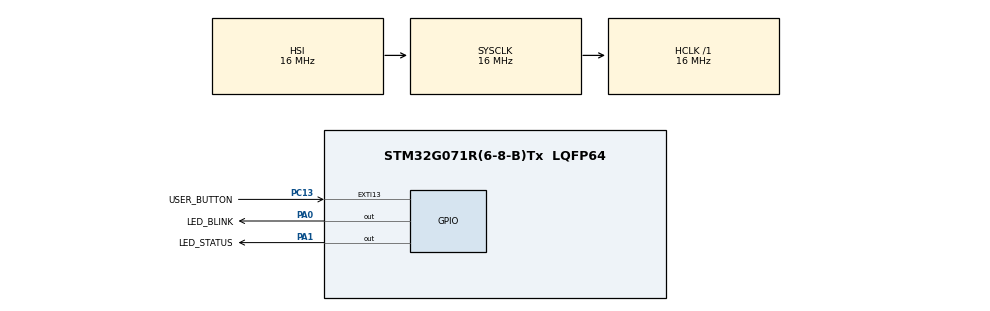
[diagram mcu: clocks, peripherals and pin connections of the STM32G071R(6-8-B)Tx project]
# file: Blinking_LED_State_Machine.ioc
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Mcu.Family=STM32G0
Mcu.Name=STM32G071R(6-8-B)Tx
Mcu.Package=LQFP64
NVIC.EXTI4_15_IRQn=true\:0\:0\:false\:false\:true\:true\:true\:true
NVIC.TIM6_DAC_LPTIM1_IRQn=true\:0\:0\:false\:false\:true\:true\:true\:true
PA0.GPIO_Label=LED_BLINK
PA0.Signal=GPIO_Output
PA1.GPIO_Label=LED_STATUS
PA1.GPIO_Speed=GPIO_SPEED_FREQ_MEDIUM
PA1.PinState=GPIO_PIN_RESET
PA1.Signal=GPIO_Output
PA13.GPIO_Label=TMS
PA13.Signal=SYS_SWDIO
PA14-BOOT0.GPIO_Label=TCK
PA14-BOOT0.Signal=SYS_SWCLK
PC13.GPIO_Label=USER_BUTTON
PC13.GPIO_ModeDefaultEXTI=GPIO_MODE_IT_RISING_FALLING
PC13.GPIO_PuPd=GPIO_PULLUP
PC13.Signal=GPXTI13
PC14-OSC32_IN\ (PC14).Signal=RCC_OSC32_IN
PC15-OSC32_OUT\ (PC15).Signal=RCC_OSC32_OUT
PF0-OSC_IN\ (PF0).GPIO_Label=MCO
PF0-OSC_IN\ (PF0).Signal=RCC_OSC_IN
ProjectManager.HeapSize=0x200
ProjectManager.StackSize=0x400
ProjectManager.TargetToolchain=STM32CubeIDE
RCC.AHBFreq_Value=16000000
RCC.CortexFreq_Value=16000000
RCC.EXTERNAL_CLOCK_VALUE=12288000
RCC.HCLKFreq_Value=16000000
RCC.HSE_VALUE=8000000
RCC.HSI_VALUE=16000000
RCC.LSE_VALUE=32768
RCC.SYSCLKFreq_VALUE=16000000
RCC.VCOOutputFreq_Value=128000000
TIM6.AutoReloadPreload=TIM_AUTORELOAD_PRELOAD_DISABLE
TIM6.Prescaler=16000-1
TIM6.TIM_MasterOutputTrigger=TIM_TRGO_UPDATE
VP_TIM6_VS_ClockSourceINT.Mode=Enable_Timer
board=NUCLEO-G071RB

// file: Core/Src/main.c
/* USER CODE BEGIN Header */
/**
  ******************************************************************************
  * @file           : main.c
  * @brief          : Main program body
  ******************************************************************************
  * @attention
  *
  * Copyright (c) 2023 STMicroelectronics.
  * All rights reserved.
  *
  * This software is licensed under terms that can be found in the LICENSE file
  * in the root directory of this software component.
  * If no LICENSE file comes with this software, it is provided AS-IS.
  *
  ******************************************************************************
  */
/* USER CODE END Header */
#include "main.h"

TIM_HandleTypeDef htim6;

void SystemClock_Config(void);
static void MX_GPIO_Init(void);
static void MX_TIM6_Init(void);

int main(void)
{

  /* MCU Configuration--------------------------------------------------------*/

  /* Reset of all peripherals, Initializes the Flash interface and the Systick. */
  HAL_Init();

  /* Configure the system clock */
  SystemClock_Config();

  /* Initialize all configured peripherals */
  MX_GPIO_Init();
  MX_TIM6_Init();
  /* USER CODE BEGIN 2 */
  BlinkingLED_StateMachine_Init();
  /* USER CODE END 2 */

  /* Infinite loop */
  /* USER CODE BEGIN WHILE */

  while (1)
  {
	  /*************** NOTE: Here background process loop for blinking led ***********************/

	  led_blink();

    /* USER CODE END WHILE */

  }
}

void SystemClock_Config(void)
{
  RCC_OscInitTypeDef RCC_OscInitStruct = {0};
  RCC_ClkInitTypeDef RCC_ClkInitStruct = {0};

  /** Configure the main internal regulator output voltage
  */
  HAL_PWREx_ControlVoltageScaling(PWR_REGULATOR_VOLTAGE_SCALE1);

  /** Initializes the RCC Oscillators according to the specified parameters
  * in the RCC_OscInitTypeDef structure.
  */
  RCC_OscInitStruct.OscillatorType = RCC_OSCILLATORTYPE_HSI;
  RCC_OscInitStruct.HSIState = RCC_HSI_ON;
  RCC_OscInitStruct.HSIDiv = RCC_HSI_DIV1;
  RCC_OscInitStruct.HSICalibrationValue = RCC_HSICALIBRATION_DEFAULT;
  RCC_OscInitStruct.PLL.PLLState = RCC_PLL_NONE;
  if (HAL_RCC_OscConfig(&RCC_OscInitStruct) != HAL_OK)
  {
    Error_Handler();
  }

  /** Initializes the CPU, AHB and APB buses clocks
  */
  RCC_ClkInitStruct.ClockType = RCC_CLOCKTYPE_HCLK|RCC_CLOCKTYPE_SYSCLK
                              |RCC_CLOCKTYPE_PCLK1;
  RCC_ClkInitStruct.SYSCLKSource = RCC_SYSCLKSOURCE_HSI;
  RCC_ClkInitStruct.AHBCLKDivider = RCC_SYSCLK_DIV1;
  RCC_ClkInitStruct.APB1CLKDivider = RCC_HCLK_DIV1;

  if (HAL_RCC_ClockConfig(&RCC_ClkInitStruct, FLASH_LATENCY_0) != HAL_OK)
  {
    Error_Handler();
  }
}

static void MX_TIM6_Init(void)
{

  TIM_MasterConfigTypeDef sMasterConfig = {0};

  htim6.Instance = TIM6;
  htim6.Init.Prescaler = 16000-1;
  htim6.Init.CounterMode = TIM_COUNTERMODE_UP;
  htim6.Init.Period = 65535;
  htim6.Init.AutoReloadPreload = TIM_AUTORELOAD_PRELOAD_DISABLE;
  if (HAL_TIM_Base_Init(&htim6) != HAL_OK)
  {
    Error_Handler();
  }
  sMasterConfig.MasterOutputTrigger = TIM_TRGO_UPDATE;
  sMasterConfig.MasterSlaveMode = TIM_MASTERSLAVEMODE_DISABLE;
  if (HAL_TIMEx_MasterConfigSynchronization(&htim6, &sMasterConfig) != HAL_OK)
  {
    Error_Handler();
  }
  /* USER CODE BEGIN TIM6_Init 2 */
  //HAL_NVIC_SetPriority(TIM6_DAC_LPTIM1_IRQn, 0, 0);
   //HAL_NVIC_EnableIRQ(TIM6_DAC_LPTIM1_IRQn);

  /* USER CODE END TIM6_Init 2 */

}

static void MX_GPIO_Init(void)
{
  GPIO_InitTypeDef GPIO_InitStruct = {0};

  /* GPIO Ports Clock Enable */
  __HAL_RCC_GPIOC_CLK_ENABLE();
  __HAL_RCC_GPIOF_CLK_ENABLE();
  __HAL_RCC_GPIOA_CLK_ENABLE();

  /*Configure GPIO pin Output Level */
  HAL_GPIO_WritePin(GPIOA, LED_BLINK_Pin|LED_STATUS_Pin, GPIO_PIN_RESET);

  /*Configure GPIO pin : USER_BUTTON_Pin */
  GPIO_InitStruct.Pin = USER_BUTTON_Pin;
  GPIO_InitStruct.Mode = GPIO_MODE_IT_RISING_FALLING;
  GPIO_InitStruct.Pull = GPIO_PULLUP;
  HAL_GPIO_Init(USER_BUTTON_GPIO_Port, &GPIO_InitStruct);

  /*Configure GPIO pin : LED_BLINK_Pin */
  GPIO_InitStruct.Pin = LED_BLINK_Pin;
  GPIO_InitStruct.Mode = GPIO_MODE_OUTPUT_PP;
  GPIO_InitStruct.Pull = GPIO_NOPULL;
  GPIO_InitStruct.Speed = GPIO_SPEED_FREQ_LOW;
  HAL_GPIO_Init(LED_BLINK_GPIO_Port, &GPIO_InitStruct);

  /*Configure GPIO pin : LED_STATUS_Pin */
  GPIO_InitStruct.Pin = LED_STATUS_Pin;
  GPIO_InitStruct.Mode = GPIO_MODE_OUTPUT_PP;
  GPIO_InitStruct.Pull = GPIO_NOPULL;
  GPIO_InitStruct.Speed = GPIO_SPEED_FREQ_MEDIUM;
  HAL_GPIO_Init(LED_STATUS_GPIO_Port, &GPIO_InitStruct);

  /* EXTI interrupt init*/
  HAL_NVIC_SetPriority(EXTI4_15_IRQn, 0, 0);
  HAL_NVIC_EnableIRQ(EXTI4_15_IRQn);

}

void Error_Handler(void)
{
  __disable_irq();
  while (1)
  {
  }
}
